VERSION "ETH_Backbone_CAN_STUB_v2.1"

NS_ :

BS_:

BU_: V2X ADAS IVI ESC MDPS VCU TEST_SCN TEST_BAS CGW IBOX SGW DCM EDR ETHB Vector__XXX

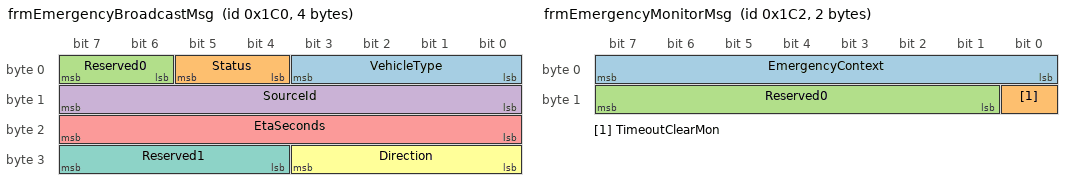
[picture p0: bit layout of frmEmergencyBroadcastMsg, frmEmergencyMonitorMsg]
BO_ 448 frmEmergencyBroadcastMsg: 4 V2X
 SG_ VehicleType  : 0|4@1+  (1,0) [0|15]  ""    V2X
 SG_ Status       : 4|2@1+  (1,0) [0|3]   ""    V2X
 SG_ Reserved0    : 6|2@1+  (1,0) [0|0]   ""    Vector__XXX
 SG_ SourceId     : 8|8@1+  (1,0) [0|255] ""    V2X
 SG_ EtaSeconds   : 16|8@1+ (1,0) [0|255] "s"   V2X
 SG_ Direction    : 24|4@1+ (1,0) [0|15]  ""    V2X
 SG_ Reserved1    : 28|4@1+ (1,0) [0|0]   ""    Vector__XXX

BO_ 450 frmEmergencyMonitorMsg: 2 V2X
 SG_ EmergencyContext : 0|8@1+ (1,0) [0|255] "" TEST_SCN,ESC
 SG_ TimeoutClearMon  : 8|1@1+ (1,0) [0|1]   "" TEST_SCN,ESC
 SG_ Reserved0        : 9|7@1+ (1,0) [0|0]   "" Vector__XXX

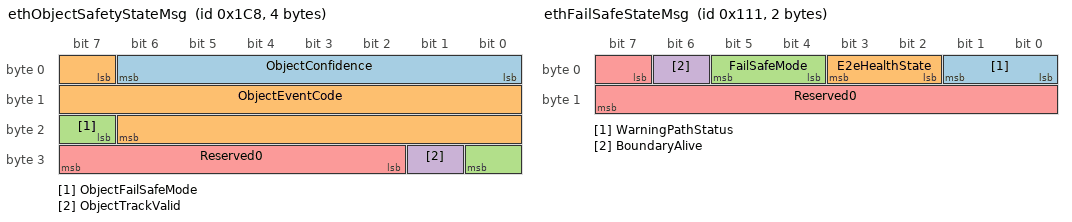
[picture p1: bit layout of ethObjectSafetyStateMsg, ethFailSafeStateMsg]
BO_ 456 ethObjectSafetyStateMsg: 4 CGW
 SG_ ObjectConfidence      : 0|7@1+   (1,0) [0|100] "%" ADAS,TEST_SCN,V2X
 SG_ ObjectEventCode       : 7|16@1+  (1,0) [0|65535] "" ADAS,TEST_SCN,V2X
 SG_ ObjectFailSafeMode    : 23|2@1+  (1,0) [0|2] "" ADAS,TEST_SCN,V2X
 SG_ ObjectTrackValid      : 25|1@1+  (1,0) [0|1] "" ADAS,TEST_SCN,V2X
 SG_ Reserved0             : 26|6@1+  (1,0) [0|0] "" Vector__XXX

BO_ 273 ethFailSafeStateMsg: 2 CGW
 SG_ WarningPathStatus : 0|2@1+ (1,0) [0|2] "" ADAS,TEST_SCN
 SG_ E2eHealthState   : 2|2@1+ (1,0) [0|2] "" ADAS,TEST_SCN
 SG_ FailSafeMode     : 4|2@1+ (1,0) [0|2] "" ADAS,TEST_SCN
 SG_ BoundaryAlive    : 6|1@1+ (1,0) [0|1] "" ADAS,TEST_SCN
 SG_ Reserved0        : 7|9@1+ (1,0) [0|0] "" Vector__XXX

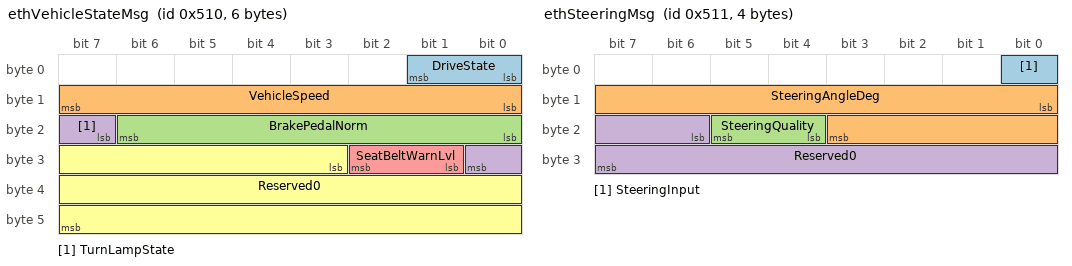
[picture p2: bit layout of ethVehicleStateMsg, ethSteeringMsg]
BO_ 1296 ethVehicleStateMsg: 6 VCU
 SG_ DriveState       : 0|2@1+  (1,0) [0|3]   ""    ADAS,TEST_SCN,ADAS
 SG_ VehicleSpeed     : 8|8@1+  (1,0) [0|255] "km/h" ADAS,TEST_SCN,ADAS
 SG_ BrakePedalNorm   : 16|7@1+ (1,0) [0|100] "%"   ADAS,TEST_SCN
 SG_ TurnLampState    : 23|2@1+ (1,0) [0|3]   ""    ADAS,TEST_SCN
 SG_ SeatBeltWarnLvl  : 25|2@1+ (1,0) [0|3]   ""    ADAS,TEST_SCN
 SG_ Reserved0        : 27|21@1+ (1,0) [0|0]  ""    Vector__XXX

BO_ 1297 ethSteeringMsg: 4 MDPS
 SG_ SteeringInput    : 0|1@1+   (1,0) [0|1]    ""    ADAS,TEST_SCN,ADAS
 SG_ SteeringAngleDeg : 8|12@1-  (1,0) [-720|720] "deg" ADAS,TEST_SCN
 SG_ SteeringQuality  : 20|2@1+  (1,0) [0|3]    ""    ADAS,TEST_SCN
 SG_ Reserved0        : 22|10@1+ (1,0) [0|0]    ""    Vector__XXX

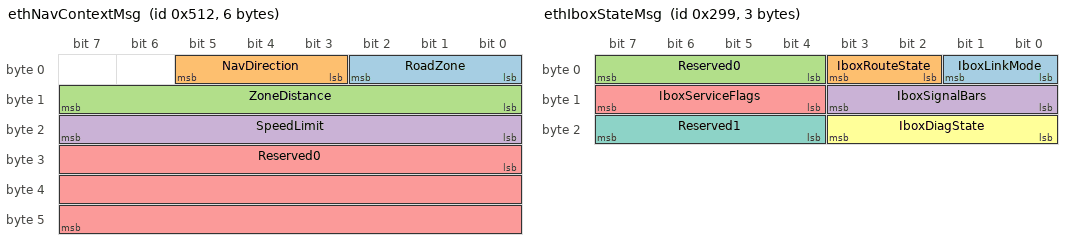
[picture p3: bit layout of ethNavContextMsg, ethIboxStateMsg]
BO_ 1298 ethNavContextMsg: 6 IVI
 SG_ RoadZone         : 0|3@1+   (1,0) [0|7]    ""    ADAS,TEST_SCN,IVI
 SG_ NavDirection     : 3|3@1+   (1,0) [0|7]    ""    ADAS,TEST_SCN,IVI
 SG_ ZoneDistance     : 8|8@1+   (1,0) [0|255]  "m"   ADAS,TEST_SCN,IVI
 SG_ SpeedLimit       : 16|8@1+  (1,0) [0|255]  "km/h" ADAS,TEST_SCN,IVI
 SG_ Reserved0        : 24|24@1+ (1,0) [0|0]    ""    Vector__XXX

BO_ 665 ethIboxStateMsg: 3 IBOX
 SG_ IboxLinkMode     : 0|2@1+ (1,0) [0|3] "" SGW,DCM,TEST_SCN
 SG_ IboxRouteState   : 2|2@1+ (1,0) [0|3] "" SGW,DCM,TEST_SCN
 SG_ Reserved0        : 4|4@1+ (1,0) [0|0] "" Vector__XXX
 SG_ IboxSignalBars   : 8|4@1+ (1,0) [0|15] "" SGW,DCM
 SG_ IboxServiceFlags : 12|4@1+ (1,0) [0|15] "" SGW,DCM,TEST_SCN
 SG_ IboxDiagState    : 16|4@1+ (1,0) [0|15] "" SGW,DCM
 SG_ Reserved1        : 20|4@1+ (1,0) [0|0] "" Vector__XXX

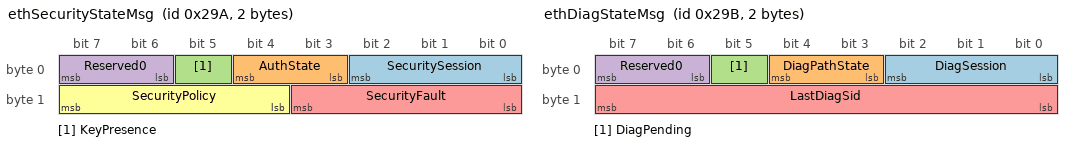
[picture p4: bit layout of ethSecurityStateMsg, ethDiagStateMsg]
BO_ 666 ethSecurityStateMsg: 2 SGW
 SG_ SecuritySession  : 0|3@1+ (1,0) [0|7] "" DCM,TEST_SCN
 SG_ AuthState        : 3|2@1+ (1,0) [0|3] "" DCM,TEST_SCN
 SG_ KeyPresence      : 5|1@1+ (1,0) [0|1] "" DCM
 SG_ Reserved0        : 6|2@1+ (1,0) [0|0] "" Vector__XXX
 SG_ SecurityFault    : 8|4@1+ (1,0) [0|15] "" DCM,TEST_SCN
 SG_ SecurityPolicy   : 12|4@1+ (1,0) [0|15] "" DCM

BO_ 667 ethDiagStateMsg: 2 DCM
 SG_ DiagSession      : 0|3@1+ (1,0) [0|7] "" TEST_SCN
 SG_ DiagPathState    : 3|2@1+ (1,0) [0|3] "" TEST_SCN
 SG_ DiagPending      : 5|1@1+ (1,0) [0|1] "" TEST_SCN
 SG_ Reserved0        : 6|2@1+ (1,0) [0|0] "" Vector__XXX
 SG_ LastDiagSid      : 8|8@1+ (1,0) [0|255] "" TEST_SCN

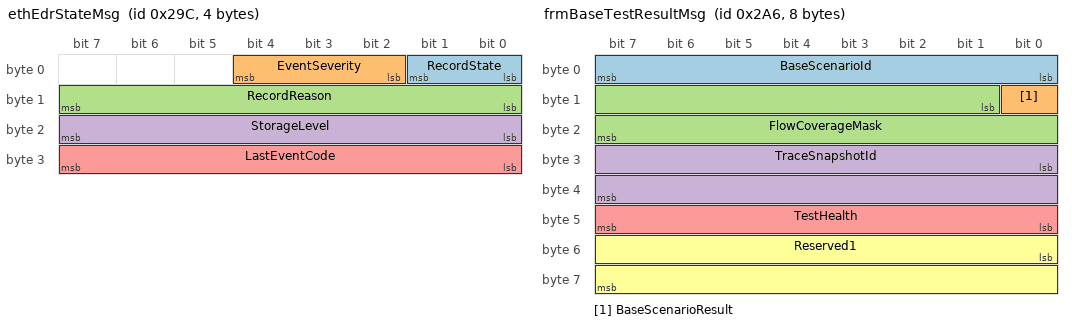
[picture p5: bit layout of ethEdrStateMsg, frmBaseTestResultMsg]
BO_ 668 ethEdrStateMsg: 4 EDR
 SG_ RecordState      : 0|2@1+ (1,0) [0|3] "" CGW,TEST_SCN
 SG_ EventSeverity    : 2|3@1+ (1,0) [0|7] "" CGW,TEST_SCN
 SG_ RecordReason     : 8|8@1+ (1,0) [0|255] "" CGW,TEST_SCN
 SG_ StorageLevel     : 16|8@1+ (1,0) [0|100] "%" CGW,TEST_SCN
 SG_ LastEventCode    : 24|8@1+ (1,0) [0|255] "" CGW,TEST_SCN

BO_ 677 frmTestResultMsg: 1 TEST_SCN
 SG_ ScenarioResult : 0|1@1+ (1,0) [0|1] "" TEST_BAS
 SG_ Reserved0      : 1|7@1+ (1,0) [0|0] "" Vector__XXX

BO_ 678 frmBaseTestResultMsg: 8 TEST_BAS
 SG_ BaseScenarioId    : 0|8@1+ (1,0) [0|255] "" TEST_SCN
 SG_ BaseScenarioResult: 8|1@1+ (1,0) [0|1]   "" TEST_SCN
 SG_ FlowCoverageMask  : 9|15@1+ (1,0) [0|32767] "" TEST_SCN
 SG_ TraceSnapshotId   : 24|16@1+ (1,0) [0|65535] "" TEST_SCN
 SG_ TestHealth        : 40|8@1+ (1,0) [0|255] "" TEST_SCN
 SG_ Reserved1         : 48|16@1+ (1,0) [0|0] "" Vector__XXX

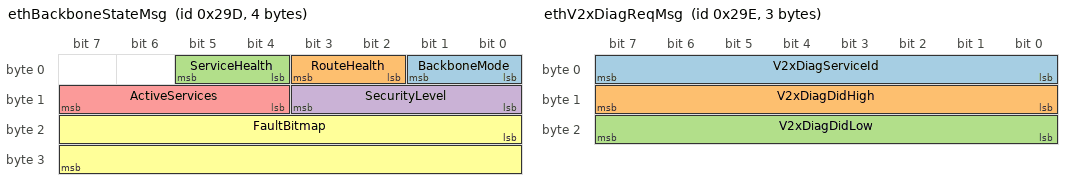
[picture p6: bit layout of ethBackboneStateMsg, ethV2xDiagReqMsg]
BO_ 669 ethBackboneStateMsg: 4 ETHB
 SG_ BackboneMode     : 0|2@1+ (1,0) [0|3] "" CGW,IBOX,SGW,DCM
 SG_ RouteHealth      : 2|2@1+ (1,0) [0|3] "" CGW,IBOX,SGW,DCM
 SG_ ServiceHealth    : 4|2@1+ (1,0) [0|3] "" CGW,IBOX,SGW,DCM
 SG_ SecurityLevel    : 8|4@1+ (1,0) [0|15] "" CGW,IBOX,SGW,DCM
 SG_ ActiveServices   : 12|4@1+ (1,0) [0|15] "" CGW,IBOX,SGW,DCM
 SG_ FaultBitmap      : 16|16@1+ (1,0) [0|65535] "" CGW,IBOX,SGW,DCM

BO_ 670 ethV2xDiagReqMsg: 3 TEST_SCN
 SG_ V2xDiagServiceId : 0|8@1+ (1,0) [0|255] "" V2X
 SG_ V2xDiagDidHigh   : 8|8@1+ (1,0) [0|255] "" V2X
 SG_ V2xDiagDidLow    : 16|8@1+ (1,0) [0|255] "" V2X

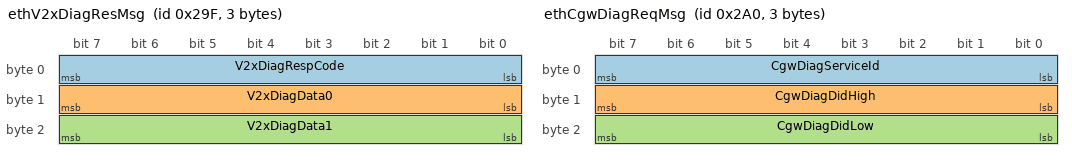
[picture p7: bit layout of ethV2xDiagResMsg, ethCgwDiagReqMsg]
BO_ 671 ethV2xDiagResMsg: 3 V2X
 SG_ V2xDiagRespCode  : 0|8@1+ (1,0) [0|255] "" TEST_SCN
 SG_ V2xDiagData0     : 8|8@1+ (1,0) [0|255] "" TEST_SCN
 SG_ V2xDiagData1     : 16|8@1+ (1,0) [0|255] "" TEST_SCN

BO_ 672 ethCgwDiagReqMsg: 3 TEST_SCN
 SG_ CgwDiagServiceId : 0|8@1+ (1,0) [0|255] "" CGW
 SG_ CgwDiagDidHigh   : 8|8@1+ (1,0) [0|255] "" CGW
 SG_ CgwDiagDidLow    : 16|8@1+ (1,0) [0|255] "" CGW

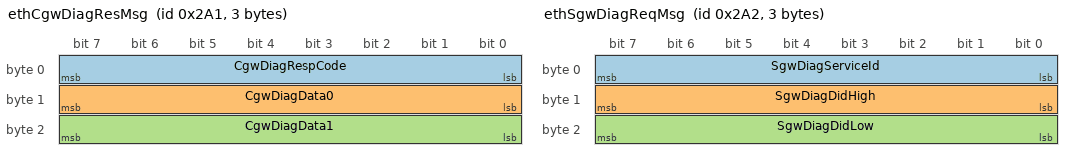
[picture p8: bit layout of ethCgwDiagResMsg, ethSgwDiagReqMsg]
BO_ 673 ethCgwDiagResMsg: 3 CGW
 SG_ CgwDiagRespCode  : 0|8@1+ (1,0) [0|255] "" TEST_SCN
 SG_ CgwDiagData0     : 8|8@1+ (1,0) [0|255] "" TEST_SCN
 SG_ CgwDiagData1     : 16|8@1+ (1,0) [0|255] "" TEST_SCN

BO_ 674 ethSgwDiagReqMsg: 3 TEST_SCN
 SG_ SgwDiagServiceId : 0|8@1+ (1,0) [0|255] "" SGW
 SG_ SgwDiagDidHigh   : 8|8@1+ (1,0) [0|255] "" SGW
 SG_ SgwDiagDidLow    : 16|8@1+ (1,0) [0|255] "" SGW

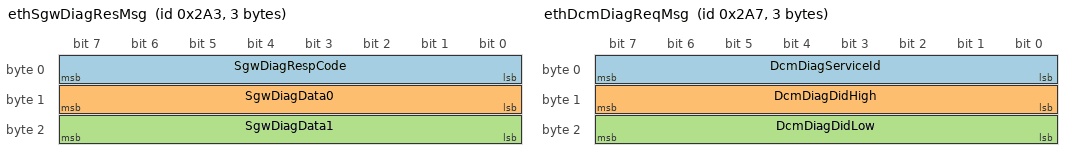
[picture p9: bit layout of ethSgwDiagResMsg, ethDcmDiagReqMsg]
BO_ 675 ethSgwDiagResMsg: 3 SGW
 SG_ SgwDiagRespCode  : 0|8@1+ (1,0) [0|255] "" TEST_SCN
 SG_ SgwDiagData0     : 8|8@1+ (1,0) [0|255] "" TEST_SCN
 SG_ SgwDiagData1     : 16|8@1+ (1,0) [0|255] "" TEST_SCN

BO_ 679 ethDcmDiagReqMsg: 3 TEST_SCN
 SG_ DcmDiagServiceId : 0|8@1+ (1,0) [0|255] "" DCM
 SG_ DcmDiagDidHigh   : 8|8@1+ (1,0) [0|255] "" DCM
 SG_ DcmDiagDidLow    : 16|8@1+ (1,0) [0|255] "" DCM

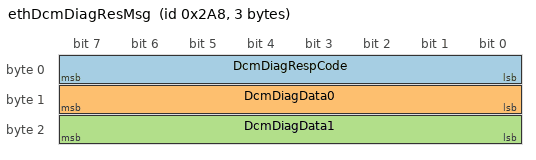
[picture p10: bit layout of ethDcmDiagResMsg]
BO_ 680 ethDcmDiagResMsg: 3 DCM
 SG_ DcmDiagRespCode  : 0|8@1+ (1,0) [0|255] "" TEST_SCN
 SG_ DcmDiagData0     : 8|8@1+ (1,0) [0|255] "" TEST_SCN
 SG_ DcmDiagData1     : 16|8@1+ (1,0) [0|255] "" TEST_SCN

CM_ BO_ 448 "E100: Emergency vehicle broadcast. Sent by V2X on ETH backbone stub through its internal V2X transport seam.";
CM_ SG_ 448 VehicleType  "1=POLICE 2=AMBULANCE";
CM_ SG_ 448 Status       "0=CLEAR 1=ACTIVE";
CM_ SG_ 448 SourceId     "Unique vehicle source ID for tiebreaker.";
CM_ SG_ 448 EtaSeconds   "Estimated time of arrival in seconds. Lower = higher priority.";
CM_ SG_ 448 Direction    "0=UNKNOWN 1=FRONT 2=REAR 3=SIDE";
CM_ BO_ 450 "E562: Emergency monitor shadow. Produced by V2X on ETH backbone stub through its internal transport seam.";
CM_ SG_ 450 EmergencyContext "Active emergency type mirrored from Core sysvar.";
CM_ SG_ 450 TimeoutClearMon  "1=timeout clear pulse active.";
CM_ BO_ 456 "E216: Object safety state frame. Produced by CGW for confidence/failsafe/event trace.";
CM_ SG_ 456 ObjectEventCode "Object alert event code (Req_138 traceability).";
CM_ SG_ 456 ObjectFailSafeMode "Object path fail-safe mode mirror.";
CM_ BO_ 273 "E789: Fail-safe state frame. Produced by CGW (Req_124).";
CM_ SG_ 273 WarningPathStatus "0=normal 1=degraded 2=failed.";
CM_ SG_ 273 E2eHealthState "0=failed 1=degraded 2=healthy.";
CM_ SG_ 273 FailSafeMode "0=normal 1=degraded 2=blocked.";
CM_ BO_ 1296 "Normalized vehicle state frame on ETH backbone stub. Produced by VCU through its internal domain transport seam.";
CM_ SG_ 1296 DriveState "0=P 1=R 2=N 3=D.";
CM_ SG_ 1296 BrakePedalNorm "Driver brake pedal normalized percentage.";
CM_ SG_ 1296 TurnLampState "0=Off 1=Left 2=Right 3=Hazard.";
CM_ BO_ 1297 "Normalized steering context frame on ETH backbone stub. Produced by MDPS through its internal domain transport seam.";
CM_ SG_ 1297 SteeringInput "1 when driver steering intervention is detected.";
CM_ SG_ 1297 SteeringQuality "Steering signal quality indicator.";
CM_ BO_ 1298 "Normalized navigation context frame on ETH backbone stub. Produced by IVI through its internal domain transport seam.";
CM_ SG_ 1298 RoadZone "0=None 1=School 2=Highway 3=Guide.";
CM_ SG_ 1298 NavDirection "0=None 1=Left 2=Right 3=Straight.";
CM_ BO_ 665 "IBOX backbone aggregation state. Produced by IBOX from ETH-backbone context and service health.";
CM_ BO_ 666 "Security gateway state. Produced by SGW from CGW/IBOX backbone security posture.";
CM_ BO_ 667 "Diagnostic backbone state. Produced by DCM from security and routing context.";
CM_ BO_ 668 "EDR backbone event recorder state. Produced by EDR from fail-safe and object-safety context.";
CM_ BO_ 669 "ETH backbone consolidated health state. Produced by ETHB service from IBOX/SGW/DCM context.";
CM_ BO_ 670 "ETH backbone runtime: V2X diagnostic request.";
CM_ BO_ 671 "ETH backbone runtime: V2X diagnostic response.";
CM_ BO_ 672 "ETH backbone runtime: CGW diagnostic request.";
CM_ BO_ 673 "ETH backbone runtime: CGW diagnostic response.";

BA_DEF_ BO_ "GenMsgCycleTime" INT 0 10000;
BA_DEF_DEF_ "GenMsgCycleTime" 0;
BA_ "GenMsgCycleTime" BO_ 450 100;
BA_ "GenMsgCycleTime" BO_ 456 100;
BA_ "GenMsgCycleTime" BO_ 273 300;
BA_ "GenMsgCycleTime" BO_ 1296 100;
BA_ "GenMsgCycleTime" BO_ 1297 100;
BA_ "GenMsgCycleTime" BO_ 1298 100;
BA_ "GenMsgCycleTime" BO_ 665 100;
BA_ "GenMsgCycleTime" BO_ 666 100;
BA_ "GenMsgCycleTime" BO_ 667 100;
BA_ "GenMsgCycleTime" BO_ 668 100;
BA_ "GenMsgCycleTime" BO_ 669 100;

VAL_ 448 VehicleType 0 "NONE" 1 "POLICE" 2 "AMBULANCE";
VAL_ 448 Status 0 "CLEAR" 1 "ACTIVE";
VAL_ 448 Direction 0 "UNKNOWN" 1 "FRONT" 2 "REAR" 3 "SIDE";
VAL_ 450 TimeoutClearMon 0 "NoClear" 1 "Clear";
VAL_ 456 ObjectFailSafeMode 0 "NORMAL" 1 "DEGRADED" 2 "BLOCKED";
VAL_ 456 ObjectTrackValid 0 "INVALID" 1 "VALID";
VAL_ 273 WarningPathStatus 0 "NORMAL" 1 "DEGRADED" 2 "FAILED";
VAL_ 273 E2eHealthState 0 "FAILED" 1 "DEGRADED" 2 "HEALTHY";
VAL_ 273 FailSafeMode 0 "NORMAL" 1 "DEGRADED" 2 "BLOCKED";
VAL_ 1296 DriveState 0 "P" 1 "R" 2 "N" 3 "D";
VAL_ 1296 TurnLampState 0 "OFF" 1 "LEFT" 2 "RIGHT" 3 "HAZARD";
VAL_ 1297 SteeringInput 0 "NO" 1 "YES";
VAL_ 1298 RoadZone 0 "NONE" 1 "SCHOOL" 2 "HIGHWAY" 3 "GUIDE";
VAL_ 1298 NavDirection 0 "NONE" 1 "LEFT" 2 "RIGHT" 3 "STRAIGHT";
VAL_ 668 RecordState 0 "Idle" 1 "Armed" 2 "Recording" 3 "Fault";
VAL_ 669 BackboneMode 0 "Init" 1 "Standby" 2 "Active" 3 "Fault";
